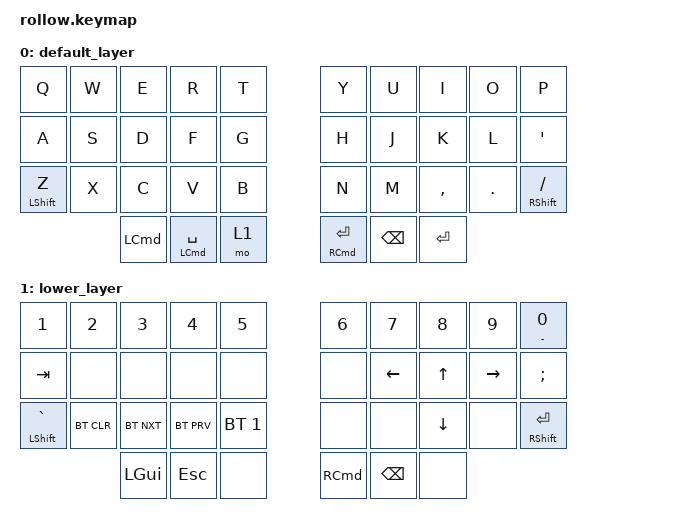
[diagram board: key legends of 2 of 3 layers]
/*
 * Copyright (c) 2020 The ZMK Contributors
 *
 * SPDX-License-Identifier: MIT
 */

#include <behaviors.dtsi>
#include <dt-bindings/zmk/keys.h>
#include <dt-bindings/zmk/bt.h>

#define COL   0
#define COLL  1
#define COLR  2

/ {
        behaviors {
        ak: auxillary_keys {
            compatible = "zmk,behavior-hold-tap";
            label = "AUXILLARY_KEYS";
            #binding-cells = <2>;
            tapping_term_ms = <200>;
            flavor = "tap-preferred";
            quick-tap-ms = <100>;
            global-quick-tap;
            bindings = <&kp>, <&kp>;
                };
        tp: tap_mods {
            compatible = "zmk,behavior-hold-tap";
            label = "TAP_MODS";
            #binding-cells = <2>;
            tapping_term_ms = <350>;
            quick-tap-ms = <200>;
            global-quick-tap;
            flavor = "tap-preferred";
            bindings = <&kp>, <&kp>;
                };
         };


        keymap {
                compatible = "zmk,keymap";

                default_layer {
/* Default
 * .----------------------------------.                    .----------------------------------.
 * |   Q  |   W  |   E  |   R  |   T  |                    |   Y  |   U  |   I  |   O  |  P   |
 * |------+------+------+------+----- |                    |------+------+------+------+------|
 * |   A  |   S  |   D  |   F  |   G  |                    |   H  |   J  |   K  |   L  |   '  |
 * |------+------+------+------+------|                    |------+------+------+------+------|
 * | Z/LS |   X  |   C  |   V  |   B  |                    |   N  |   M  |   ,  |   .  | //RS |
 * '----------------------------------/                    \----------------------------------'
 *           | LCMD | SPC/ | / LAYR1 /                      \ RET/ \  | BSPC | RET  |
 *           |      | LCMD |/       /                        \ RCMD \ |      |      |
 *           '-------------''------'                          '------''-------------'
 *
 *   Encoder Left: Up <-> Down
 *   Encoder Right: Left <-> Right
 */
                        bindings = <
    &kp Q &kp W &kp E &kp R &kp T    &kp Y &kp U  &kp I     &kp O   &kp P
    &kp A &kp S &kp D &kp F &kp G    &kp H &kp J  &kp K     &kp L   &kp APOS
    &mt LSHIFT Z &kp X &kp C &kp V &kp B    &kp N &kp M  &kp COMMA &kp DOT &mt RSHIFT FSLH
         &kp LCMD &tp LCMD SPACE &mo 1    &mt RCMD RET &kp BSPC &kp RET
                        >;

                        sensor-bindings = <&inc_dec_kp DOWN UP &inc_dec_kp RIGHT LEFT>;
                };

                lower_layer {
/* LOWER
 * .----------------------------------.                    .----------------------------------.
 * |   1  |  2   |  3   |  4   |  5   |                    |   6  |   7  |   8  |   9  | -/0  |
 * |------+------+------+------+------|                    |------+------+------+------+------|
 * |  TAB |      |      |      |      |                    |      | LEFT |  UP  | RIGHT|  ;   |
 * |------+------+------+------+------|                    |------+------+------+------+------|
 * |GRV/RS|      |      |      |      |                    |      |      | DOWN |      |RET/LS|
 * '----------------------------------/                    \----------------------------------'
 *           |  GUI |  ESC | /       /                      \ RCMD \  | BSPC |      |
 *           |      |      |/       /                        \      \ |      |      |
 *           '-------------''------'                          '------''-------------'
 * 
 *   Encoder Left: PG_UP <-> PG_DN
 *   Encoder Right: Volume Down <-> Volume Up
 */
                        bindings = <
    &kp N1 &kp N2 &kp N3 &kp N4 &kp N5         &kp N6 &kp N7   &kp N8   &kp N9    &ak MINUS N0 
       &kp TAB &none &none &none &none         &none  &kp LEFT &kp UP   &kp RIGHT &kp SEMI 
 &mt LSHIFT GRAVE &bt BT_CLR &bt BT_NXT &bt BT_PRV &bt BT_SEL 1    &none  &none    &kp DOWN &none &mt RSHIFT RET 
                &kp LGUI &kp ESC &none         &kp RCMD &kp BSPC &none
                            >;

           sensor-bindings = <&inc_dec_kp PG_UP PG_DN &inc_dec_kp C_VOL_DOWN C_VOL_UP>;
                };

                raise_layer {
/* RAISE
 * .-----------------------------------------.                    .-----------------------------------------.
 * | ESC  |   !  |   @  |   #  |   $  |   %  |                    |   ^  |   &  |   *  |   (  |   )  | BKSP |
 * |------+------+------+------+------+------|                    |------+------+------+------+------+------|
 * | CTRL |      |      | Prev | Next |      |                    |   -  |   =  |   {  |   }  |  "|" |   `  |
 * |------+------+------+------+------+------|                    |------+------+------+------+------+------|
 * | SHFT |      |      |      |      |      |-------.    .-------|   _  |   +  |   [  |   ]  |   \  |   ~  |
 * '-----------------------------------------/       /     \      \-----------------------------------------'
 *                          | Play |      | / Space /       \ Enter\  |      |  ALT |
 *                          | Paus |      |/       /         \      \ |      |      |
 *                          '------------''------'            '------''-------------'
 *
 *   Encoder Left: -
 *   Encoder Right: VOL_UP <-> VOL_D
 */
                        bindings = <
    &kp  ESC  &kp EXCL  &kp AT  &kp HASH   &kp DLLR   &kp PRCNT   &kp CARET &kp AMPS  &kp KP_MULTIPLY &kp LPAR &kp RPAR &kp BSPC
    &kp LCTRL &trans    &trans  &kp C_PREV &kp C_NEXT &trans      &kp MINUS &kp EQUAL &kp LBKT        &kp RBKT &kp PIPE &kp GRAVE
    &kp LSHFT &trans    &trans  &trans     &trans     &trans      &trans    &trans    &trans          &trans   &kp BSLH &kp TILDE
                                   &kp LGUI &trans &kp SPACE   &kp RET &trans &kp RALT
                        >;
   
                        sensor-bindings = <&inc_dec_kp C_VOL_UP C_VOL_DN &inc_dec_kp PG_UP PG_DN>;
                };
 
        };
};
